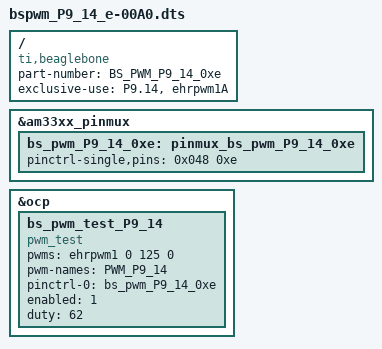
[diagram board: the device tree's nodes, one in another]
/*
 * Copyright (C) 2013 CircuitCo
 * Copyright (C) 2013 Texas Instruments
 *
 * This program is free software; you can redistribute it and/or modify
 * it under the terms of the GNU General Public License version 2 as
 * published by the Free Software Foundation.
 *
 * This is a template-generated file from BoneScript
 */
/dts-v1/;
/plugin/;

/ {
	compatible = "ti,beaglebone", "ti,beaglebone-black";

	/* identification */
	part-number = "BS_PWM_P9_14_0xe";

	/* state the resources this cape uses */
	exclusive-use =
		/* the pin header uses */
		"P9.14",
		/* the hardware IP uses */
		"ehrpwm1A";

	fragment@0 {
		target = <&am33xx_pinmux>;
		__overlay__ {
			bs_pwm_P9_14_0xe: pinmux_bs_pwm_P9_14_0xe {
				pinctrl-single,pins = <0x048 0xe>;
			};
		};
	};

	fragment@1 {
		target = <&ocp>;
		__overlay__ {
			bs_pwm_test_P9_14 {
				compatible	= "pwm_test";
				pwms 		= <&ehrpwm1 0 125 0>;
				pwm-names 	= "PWM_P9_14";

				pinctrl-names	= "default";
				pinctrl-0	= <&bs_pwm_P9_14_0xe>;

				enabled		= <1>;
				duty		= <62>;
				status 		= "okay";
			};
		};
	};
};

